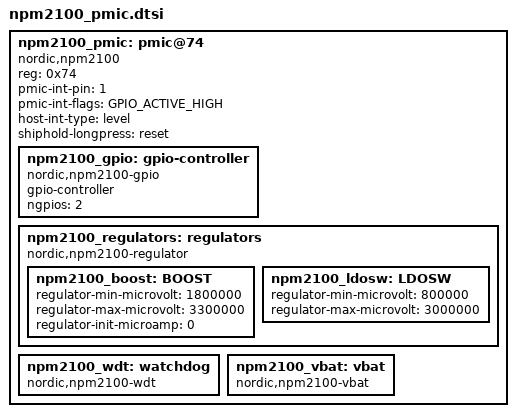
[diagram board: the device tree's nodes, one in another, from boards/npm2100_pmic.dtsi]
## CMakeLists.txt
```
# Copyright (c) 2025 Nordic Semiconductor ASA
# SPDX-License-Identifier: LicenseRef-Nordic-5-Clause

cmake_minimum_required(VERSION 3.20.0)

find_package(Zephyr REQUIRED HINTS $ENV{ZEPHYR_BASE})

project(npm2100_one_button)
target_sources(app PRIVATE src/main.c)
```

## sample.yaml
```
# Copyright (c) 2025 Nordic Semiconductor ASA
# SPDX-License-Identifier: LicenseRef-Nordic-5-Clause
sample:
  name: nPM2100 one button

common:
  integration_platforms:
    - nrf52840dk/nrf52840
    - nrf5340dk/nrf5340/cpuapp
    - nrf54l15dk/nrf54l15/cpuapp
  platform_allow:
    - nrf52840dk/nrf52840
    - nrf5340dk/nrf5340/cpuapp
    - nrf54l15dk/nrf54l15/cpuapp
  tags:
    - pmic
    - ci_samples_pmic

tests:
  sample.npm2100_one_button_compile:
    sysbuild: true
    build_only: true
    platform_allow:
      - nrf52840dk/nrf52840
      - nrf5340dk/nrf5340/cpuapp
      - nrf54l15dk/nrf54l15/cpuapp
    tags:
      - sysbuild
      - ci_samples_pmic
```

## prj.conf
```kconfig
# Copyright (c) 2025 Nordic Semiconductor ASA
# SPDX-License-Identifier: LicenseRef-Nordic-5-Clause

CONFIG_SHELL=y
CONFIG_LOG=y
CONFIG_GPIO=y
CONFIG_REGULATOR=y
CONFIG_I2C=y
CONFIG_I2C_SHELL=y
```

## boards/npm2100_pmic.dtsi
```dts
/*
 * Copyright (c) 2025 Nordic Semiconductor ASA
 *
 * SPDX-License-Identifier: LicenseRef-Nordic-5-Clause
 */

npm2100_pmic: pmic@74 {
	compatible = "nordic,npm2100";
	reg = <0x74>;
	pmic-int-pin = <1>;
	pmic-int-flags = <GPIO_ACTIVE_HIGH>;
	host-int-type = "level";
	shiphold-longpress = "reset";

	npm2100_gpio: gpio-controller {
		compatible = "nordic,npm2100-gpio";
		gpio-controller;
		#gpio-cells = <2>;
		ngpios = <2>;
	};

	npm2100_regulators: regulators {
		compatible = "nordic,npm2100-regulator";

		/* limits are set to min/max allowed values */
		npm2100_boost: BOOST {
			regulator-min-microvolt = <1800000>;
			regulator-max-microvolt = <3300000>;
			regulator-init-microamp = <0>;
		};

		npm2100_ldosw: LDOSW {
			regulator-min-microvolt = <800000>;
			regulator-max-microvolt = <3000000>;
		};
	};

	npm2100_wdt: watchdog {
		compatible = "nordic,npm2100-wdt";
	};

	npm2100_vbat: vbat {
		compatible = "nordic,npm2100-vbat";
	};
};
```

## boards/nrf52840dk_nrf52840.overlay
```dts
/*
 * Copyright (c) 2025 Nordic Semiconductor ASA
 *
 * SPDX-License-Identifier: LicenseRef-Nordic-5-Clause
 */

#include <dt-bindings/regulator/npm2100.h>

&i2c0_default {
	group1 {
		bias-pull-up;
	};
};

&arduino_i2c {
	#include "npm2100_pmic.dtsi"
};

&npm2100_pmic {
	host-int-gpios = <&gpio1 12 GPIO_ACTIVE_HIGH>;
};
```

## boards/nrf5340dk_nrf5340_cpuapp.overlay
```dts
/*
 * Copyright (c) 2025 Nordic Semiconductor ASA
 *
 * SPDX-License-Identifier: LicenseRef-Nordic-5-Clause
 */

#include <dt-bindings/regulator/npm2100.h>

&i2c1_default {
	group1 {
		bias-pull-up;
	};
};

&arduino_i2c {
	#include "npm2100_pmic.dtsi"
};

&npm2100_pmic {
	host-int-gpios = <&gpio1 12 GPIO_ACTIVE_HIGH>;
};
```

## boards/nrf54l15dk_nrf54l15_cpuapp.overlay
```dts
/*
 * Copyright (c) 2025 Nordic Semiconductor ASA
 *
 * SPDX-License-Identifier: LicenseRef-Nordic-5-Clause
 */

&pinctrl {
	i2c21_default: i2c21_default {
		group1 {
			psels = <NRF_PSEL(TWIM_SDA, 1, 11)>,
				<NRF_PSEL(TWIM_SCL, 1, 12)>;
			bias-pull-up;
		};
	};

	i2c21_sleep: i2c21_sleep {
		group1 {
			psels = <NRF_PSEL(TWIM_SDA, 1, 11)>,
				<NRF_PSEL(TWIM_SCL, 1, 12)>;
			low-power-enable;
		};
	};
};

&i2c21 {
	compatible = "nordic,nrf-twim";
	status = "okay";
	pinctrl-0 = <&i2c21_default>;
	pinctrl-1 = <&i2c21_sleep>;
	pinctrl-names = "default", "sleep";

	#include "npm2100_pmic.dtsi"
};

&npm2100_pmic {
	host-int-gpios = <&gpio1 8 GPIO_ACTIVE_HIGH>;
};
```

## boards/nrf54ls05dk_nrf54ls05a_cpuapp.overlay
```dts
/*
 * Copyright (c) 2026 Nordic Semiconductor ASA
 *
 * SPDX-License-Identifier: LicenseRef-Nordic-5-Clause
 */

&pinctrl {
	i2c21_default: i2c21_default {
		group1 {
			psels = <NRF_PSEL(TWIM_SDA, 1, 11)>,
				<NRF_PSEL(TWIM_SCL, 1, 12)>;
			bias-pull-up;
		};
	};

	i2c21_sleep: i2c21_sleep {
		group1 {
			psels = <NRF_PSEL(TWIM_SDA, 1, 11)>,
				<NRF_PSEL(TWIM_SCL, 1, 12)>;
			low-power-enable;
		};
	};
};

&i2c21 {
	status = "okay";
	pinctrl-0 = <&i2c21_default>;
	pinctrl-1 = <&i2c21_sleep>;
	pinctrl-names = "default", "sleep";

	#include "npm2100_pmic.dtsi"
};

&npm2100_pmic {
	host-int-gpios = <&gpio1 8 GPIO_ACTIVE_HIGH>;
};
```

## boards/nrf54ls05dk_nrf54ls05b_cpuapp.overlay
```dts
/*
 * Copyright (c) 2026 Nordic Semiconductor ASA
 *
 * SPDX-License-Identifier: LicenseRef-Nordic-5-Clause
 */

&pinctrl {
	i2c21_default_alt: i2c21_default_alt {
		group1 {
			psels = <NRF_PSEL(TWIM_SDA, 1, 11)>,
				<NRF_PSEL(TWIM_SCL, 1, 12)>;
			bias-pull-up;
		};
	};

	i2c21_sleep_alt: i2c21_sleep_alt {
		group1 {
			psels = <NRF_PSEL(TWIM_SDA, 1, 11)>,
				<NRF_PSEL(TWIM_SCL, 1, 12)>;
			low-power-enable;
		};
	};
};

&i2c21 {
	status = "okay";
	pinctrl-0 = <&i2c21_default_alt>;
	pinctrl-1 = <&i2c21_sleep_alt>;
	pinctrl-names = "default", "sleep";

	#include "npm2100_pmic.dtsi"
};

&npm2100_pmic {
	host-int-gpios = <&gpio1 8 GPIO_ACTIVE_HIGH>;
};
```

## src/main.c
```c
/*
 * Copyright (c) 2025 Nordic Semiconductor ASA
 * SPDX-License-Identifier: LicenseRef-Nordic-5-Clause
 */

#include <zephyr/logging/log_ctrl.h>
#include <zephyr/device.h>
#include <zephyr/drivers/gpio.h>
#include <zephyr/drivers/mfd/npm2100.h>
#include <zephyr/drivers/regulator.h>

#define FLASH_FAST_MS	100
#define FLASH_SLOW_MS	500
#define PRESS_SHORT_MS	1000
#define PRESS_MEDIUM_MS 5000

static int flash_time_ms = FLASH_SLOW_MS;
static bool shipmode;

static const struct gpio_dt_spec led = GPIO_DT_SPEC_GET(DT_ALIAS(led0), gpios);
static const struct device *pmic = DEVICE_DT_GET(DT_NODELABEL(npm2100_pmic));
static const struct device *regulators = DEVICE_DT_GET(DT_NODELABEL(npm2100_regulators));

static void event_callback(const struct device *dev, struct gpio_callback *cb, uint32_t events)
{
	static int64_t press_t;

	if (events & BIT(NPM2100_EVENT_SYS_SHIPHOLD_FALL)) {
		press_t = k_uptime_get();
	}

	if (events & BIT(NPM2100_EVENT_SYS_SHIPHOLD_RISE)) {
		int64_t delta_t = k_uptime_get() - press_t;

		if (delta_t < PRESS_SHORT_MS) {
			printk("Short press\n");
			flash_time_ms = FLASH_FAST_MS;
		} else if (delta_t < PRESS_MEDIUM_MS) {
			printk("Medium press\n");
			flash_time_ms = FLASH_SLOW_MS;
		} else {
			shipmode = true;
		}
	}
}

static bool configure_events(void)
{
	int ret;
	static struct gpio_callback event_cb;

	if (!device_is_ready(pmic)) {
		printk("Error: PMIC device not ready.\n");
		return false;
	}

	if (!device_is_ready(regulators)) {
		printk("Error: Regulator device not ready.\n");
		return false;
	}

	gpio_init_callback(&event_cb, event_callback,
			   BIT(NPM2100_EVENT_SYS_SHIPHOLD_FALL) |
				   BIT(NPM2100_EVENT_SYS_SHIPHOLD_RISE));

	ret = mfd_npm2100_add_callback(pmic, &event_cb);

	if (ret < 0) {
		printk("Error: failed to add a PMIC event callback.\n");
		return false;
	}

	return true;
}

static bool configure_ui(void)
{
	int ret;

	if (!gpio_is_ready_dt(&led)) {
		printk("Error: led device %s is not ready.\n", led.port->name);
		return false;
	}

	ret = gpio_pin_configure_dt(&led, GPIO_OUTPUT);

	if (ret < 0) {
		printk("Error: failed to configure led device %s.\n", led.port->name);
		return false;
	}

	printk("Set up led at %s pin %d\n", led.port->name, led.pin);

	return true;
}

int main(void)
{
	int ret;

	if (!configure_ui()) {
		return 0;
	}

	if (!configure_events()) {
		return 0;
	}

	printk("PMIC device ok\n");

	while (1) {
		if (shipmode) {
			shipmode = false;
			printk("Ship mode...\n");
			/* make sure to display the message before shutting down */
			LOG_PROCESS();

			ret = regulator_parent_ship_mode(regulators);
			if (ret < 0) {
				printk("Error: failed to enter ship mode.\n");
			}
		}
		(void)gpio_pin_toggle_dt(&led);
		k_msleep(flash_time_ms);
	}
}
```
